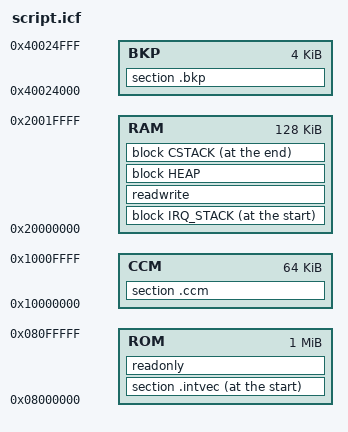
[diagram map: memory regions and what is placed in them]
/*******************************************************************************
@file     stm32f4xx.icf
@author   Rajmund Szymanski
@date     11.12.2019
@brief    Linker script for STM32F407VG device with 1024KB FLASH and 192KB RAM
*******************************************************************************/

define symbol __ROM_start__ = 0x08000000;
define symbol __ROM_size__  = 1024K; // 0x00100000
define symbol __ROM_end__   = __ROM_start__+__ROM_size__;

define symbol __CCM_start__ = 0x10000000;
define symbol __CCM_size__  = 64K; // 0x00010000
define symbol __CCM_end__   = __CCM_start__+__CCM_size__;

define symbol __RAM_start__ = 0x20000000;
define symbol __RAM_size__  = 128K; // 0x00020000
define symbol __RAM_end__   = __RAM_start__+__RAM_size__;

define symbol __BKP_start__ = 0x40024000;
define symbol __BKP_size__  = 4K; // 0x00001000
define symbol __BKP_end__   = __BKP_start__+__BKP_size__;

define memory MEM with size = 4G;
define region ROM = MEM:[ from __ROM_start__ size __ROM_size__ ];
define region CCM = MEM:[ from __CCM_start__ size __CCM_size__ ];
define region RAM = MEM:[ from __RAM_start__ size __RAM_size__ ];
define region BKP = MEM:[ from __BKP_start__ size __BKP_size__ ];

if (!isdefinedsymbol(main_stack_size)) {
define symbol main_stack_size = 0;
}
if (!isdefinedsymbol(proc_stack_size)) {
define symbol proc_stack_size = 0;
}
define symbol __main_stack_size = (((main_stack_size)+7)&(~7));
define symbol __proc_stack_size = (((proc_stack_size)+7)&(~7));

define block IRQ_STACK with alignment = 8, size = __main_stack_size {};
define block    CSTACK with alignment = 8, size = __proc_stack_size {};
define block      HEAP with alignment = 8                           {};

initialize by copy    { readwrite       };
do not initialize     { section .noinit };
keep                  { section .intvec };
place at start of ROM { section .intvec };
place in          ROM { readonly        };
place in          CCM { section .ccm    };
place at start of RAM { block IRQ_STACK };
place in          RAM { readwrite       };
place in          RAM { block HEAP      };
place at end of   RAM { block CSTACK    };
place in          BKP { section .bkp    };

if (__main_stack_size > 0) {
define exported symbol __initial_msp = __RAM_start__ + __main_stack_size;
} else {
define exported symbol __initial_msp = __RAM_end__   - __proc_stack_size;
}
if (__proc_stack_size > 0) {
define exported symbol __initial_sp  = __RAM_end__;
} else {
define exported symbol __initial_sp  = __initial_msp;
}
define exported symbol HEAP$$Limit   = __RAM_end__   - __proc_stack_size;
